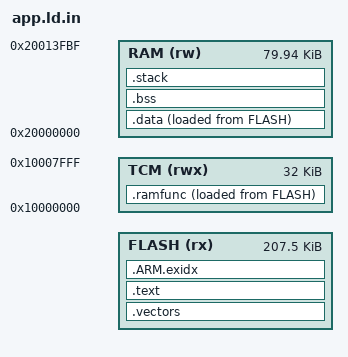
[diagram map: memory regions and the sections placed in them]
/* app.ld.in — the application-image linker template. build.sh instantiates it with SLOT_BASE (A or B) + IMG_HDR_LEN 0x200:
 * the image body starts at slot + 0x200 (the signed header sits in front — boot/image.h), the vector table first.
 * TCM (0x1000 0000, 32 KB) carries the control-ISR code (.ramfunc): flash program/erase never stalls it (§3.5).
 * SRAM0 ends 64 bytes short of 0x2001 4000 — that tail is the no-init boot handoff (flash_map.h FM_HANDOFF). */
MEMORY
{
  FLASH (rx)  : ORIGIN = @SLOT_BASE@ + 0x200, LENGTH = 0x34000 - 0x200
  TCM   (rwx) : ORIGIN = 0x10000000, LENGTH = 32K
  RAM   (rw)  : ORIGIN = 0x20000000, LENGTH = 0x13FC0
}
ENTRY(reset_handler)
SECTIONS
{
  .vectors : { KEEP(*(.vectors)) } > FLASH

  /* .ramfunc is placed BEFORE .text so its input-section patterns win — a later generic *(.text*) would swallow them */
  _siramfunc = LOADADDR(.ramfunc);
  .ramfunc : {
    . = ALIGN(4); _sramfunc = .;
    *(.ramfunc*)
    */pfc.o(.text* .rodata*) */llc.o(.text* .rodata*)     /* the 100 kHz law and the modulator, with their tables (ZVS_FN) */
    */ctl.o(.text* .rodata*)                              /* the 10 kHz regulator kernel (pmp_reg_step and its reset) */
    */lib.o(.text*)                                       /* memset / memcpy — grid_sample clears its accumulators */
    */app.o(.text.app_pfc_isr* .text.app_llc_isr* .text.app_fault_isr* .text.az_add*)
    */meas.o(.text.grid_sample* .rodata*)
    */adc.o(.text.adc_read_pfc*)
    */hrtimer.o(.text.hrtimer_pfc_apply* .text.hrtimer_llc_apply* .text.hrtimer_fault_read_clear* .rodata*)   /* PFC_ST */
    . = ALIGN(4); _eramfunc = .;
  } > TCM AT> FLASH

  .text : {
    *(.text*) *(.rodata*)
    . = ALIGN(4);
  } > FLASH
  .ARM.exidx : { *(.ARM.exidx*) } > FLASH

  _sidata = LOADADDR(.data);
  .data : { . = ALIGN(4); _sdata = .; *(.data*); . = ALIGN(4); _edata = .; } > RAM AT> FLASH
  .bss : { . = ALIGN(4); _sbss = .; *(.bss*) *(COMMON); . = ALIGN(4); _ebss = .; } > RAM

  .stack (NOLOAD) : {
    . = ALIGN(8);
    _sstack = ORIGIN(RAM) + LENGTH(RAM) - 8K;             /* 8 KB main stack, painted at reset (F.36 supervision) */
    . = _sstack + 8K;
    _estack = .;
  } > RAM
  _estack_top = ORIGIN(RAM) + LENGTH(RAM);

  ASSERT(_ebss <= _sstack, "RAM overflow into the stack region")
}
